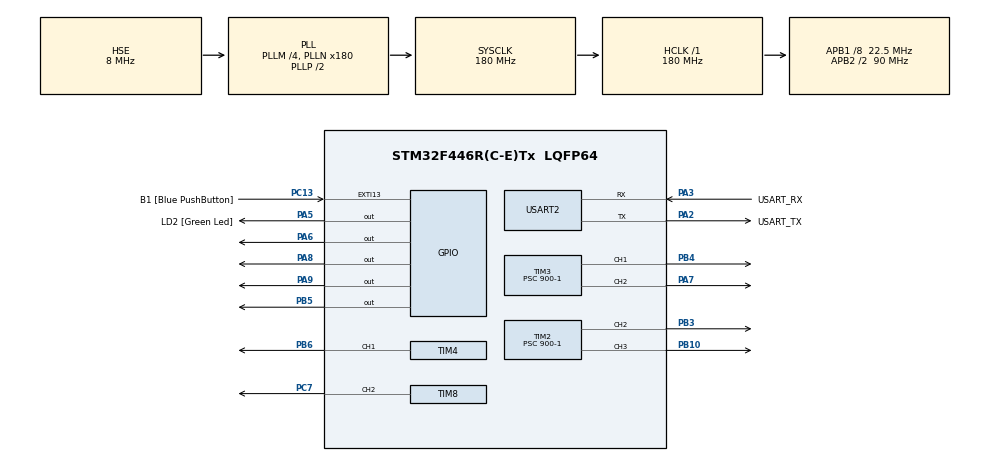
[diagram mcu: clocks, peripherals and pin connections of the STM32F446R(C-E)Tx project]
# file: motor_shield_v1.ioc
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Dma.Request0=USART2_RX
Dma.USART2_RX.0.Direction=DMA_PERIPH_TO_MEMORY
Dma.USART2_RX.0.FIFOMode=DMA_FIFOMODE_DISABLE
Dma.USART2_RX.0.Instance=DMA1_Stream5
Dma.USART2_RX.0.MemDataAlignment=DMA_MDATAALIGN_BYTE
Dma.USART2_RX.0.MemInc=DMA_MINC_ENABLE
Dma.USART2_RX.0.Mode=DMA_NORMAL
Dma.USART2_RX.0.PeriphDataAlignment=DMA_PDATAALIGN_BYTE
Dma.USART2_RX.0.PeriphInc=DMA_PINC_DISABLE
Dma.USART2_RX.0.Priority=DMA_PRIORITY_LOW
Mcu.Family=STM32F4
Mcu.Name=STM32F446R(C-E)Tx
Mcu.Package=LQFP64
NVIC.DMA1_Stream5_IRQn=true\:0\:0\:false\:false\:true\:false\:true\:true
NVIC.PriorityGroup=NVIC_PRIORITYGROUP_0
NVIC.USART2_IRQn=true\:0\:0\:false\:false\:true\:true\:true\:true
PA13.GPIO_Label=TMS
PA13.Mode=Serial_Wire
PA13.Signal=SYS_JTMS-SWDIO
PA14.GPIO_Label=TCK
PA14.Mode=Serial_Wire
PA14.Signal=SYS_JTCK-SWCLK
PA2.GPIO_Label=USART_TX
PA2.Mode=Asynchronous
PA2.Signal=USART2_TX
PA3.GPIO_Label=USART_RX
PA3.Mode=Asynchronous
PA3.Signal=USART2_RX
PA5.GPIO_Label=LD2 [Green Led]
PA5.Signal=GPIO_Output
PA6.Signal=GPIO_Output
PA7.Signal=S_TIM3_CH2
PA8.Signal=GPIO_Output
PA9.Signal=GPIO_Output
PB10.Signal=S_TIM2_CH3
PB3.Signal=S_TIM2_CH2
PB4.Signal=S_TIM3_CH1
PB5.Signal=GPIO_Output
PB6.Signal=S_TIM4_CH1
PC13.GPIO_Label=B1 [Blue PushButton]
PC13.GPIO_ModeDefaultEXTI=GPIO_MODE_IT_FALLING
PC13.Signal=GPXTI13
PC14-OSC32_IN.Mode=LSE-External-Oscillator
PC14-OSC32_IN.Signal=RCC_OSC32_IN
PC15-OSC32_OUT.Mode=LSE-External-Oscillator
PC15-OSC32_OUT.Signal=RCC_OSC32_OUT
PC7.Signal=S_TIM8_CH2
PH0-OSC_IN.Mode=HSE-External-Oscillator
PH0-OSC_IN.Signal=RCC_OSC_IN
PH1-OSC_OUT.Mode=HSE-External-Oscillator
PH1-OSC_OUT.Signal=RCC_OSC_OUT
ProjectManager.HeapSize=0x200
ProjectManager.StackSize=0x400
ProjectManager.TargetToolchain=MDK-ARM V5.32
RCC.48MHZClocksFreq_Value=84000000
RCC.AHBFreq_Value=180000000
RCC.APB1CLKDivider=RCC_HCLK_DIV8
RCC.APB1Freq_Value=22500000
RCC.APB1TimFreq_Value=45000000
RCC.APB2CLKDivider=RCC_HCLK_DIV2
RCC.APB2Freq_Value=90000000
RCC.APB2TimFreq_Value=180000000
RCC.CortexFreq_Value=180000000
RCC.FLatency-AdvancedSettings=FLASH_LATENCY_5
RCC.HCLKFreq_Value=180000000
RCC.HSE_VALUE=8000000
RCC.HSI_VALUE=16000000
RCC.PLLM=4
RCC.PLLN=180
RCC.PLLSourceVirtual=RCC_PLLSOURCE_HSE
RCC.SYSCLKFreq_VALUE=180000000
RCC.SYSCLKSource=RCC_SYSCLKSOURCE_PLLCLK
RCC.USBFreq_Value=180000000
RCC.VCOOutputFreq_Value=360000000
SH.S_TIM2_CH2.0=TIM2_CH2,PWM Generation2 CH2
SH.S_TIM2_CH3.0=TIM2_CH3,PWM Generation3 CH3
SH.S_TIM3_CH1.0=TIM3_CH1,PWM Generation1 CH1
SH.S_TIM3_CH2.0=TIM3_CH2,PWM Generation2 CH2
SH.S_TIM4_CH1.0=TIM4_CH1,PWM Generation1 CH1
SH.S_TIM8_CH2.0=TIM8_CH2,PWM Generation2 CH2
TIM2.Channel-PWM\ Generation2\ CH2=TIM_CHANNEL_2
TIM2.Channel-PWM\ Generation3\ CH3=TIM_CHANNEL_3
TIM2.Period=1000-1
TIM2.Prescaler=900-1
TIM3.Channel-PWM\ Generation1\ CH1=TIM_CHANNEL_1
TIM3.Channel-PWM\ Generation2\ CH2=TIM_CHANNEL_2
TIM3.Period=1000-1
TIM3.Prescaler=900-1
TIM4.Channel-PWM\ Generation1\ CH1=TIM_CHANNEL_1
TIM4.Period=1000-1
TIM4.Prescaler=900-1
TIM8.Channel-PWM\ Generation2\ CH2=TIM_CHANNEL_2
TIM8.Period=1000-1
TIM8.Prescaler=900-1
USART2.VirtualMode=VM_ASYNC
VP_TIM2_VS_ClockSourceINT.Mode=Internal
VP_TIM3_VS_ClockSourceINT.Mode=Internal
VP_TIM4_VS_ClockSourceINT.Mode=Internal
VP_TIM8_VS_ClockSourceINT.Mode=Internal
board=NUCLEO-F446RE

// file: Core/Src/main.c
/* USER CODE BEGIN Header */
/**
  ******************************************************************************
  * @file           : main.c
  * @brief          : Main program body
  ******************************************************************************
  * @attention
  *
  * Copyright (c) 2023 STMicroelectronics.
  * All rights reserved.
  *
  * This software is licensed under terms that can be found in the LICENSE file
  * in the root directory of this software component.
  * If no LICENSE file comes with this software, it is provided AS-IS.
  *
  ******************************************************************************
  */
/* USER CODE END Header */
#include "main.h"
#include "dma.h"
#include "tim.h"
#include "usart.h"
#include "gpio.h"

void SystemClock_Config(void);

int main(void)
{

  /* MCU Configuration--------------------------------------------------------*/

  /* Reset of all peripherals, Initializes the Flash interface and the Systick. */
  HAL_Init();

  /* Configure the system clock */
  SystemClock_Config();

  /* Initialize all configured peripherals */
  MX_GPIO_Init();
  MX_DMA_Init();
  MX_USART2_UART_Init();
  MX_TIM4_Init();
  MX_TIM3_Init();
  MX_TIM8_Init();
  MX_TIM2_Init();
  /* USER CODE BEGIN 2 */
	HAL_UARTEx_ReceiveToIdle_DMA(&huart2, RxBuf, RxBuf_SIZE);
	__HAL_DMA_DISABLE_IT(&hdma_usart2_rx, DMA_IT_HT);

	/* USER CODE END 2 */

  /* Infinite loop */
  /* USER CODE BEGIN WHILE */

	printf("Test start\r\n"); // Print for debug.
	core_config();
	ms1_motor_control(&motor_shield_v1,M1,1,1000);

  while (1)
  {
    /* USER CODE END WHILE */

    /* USER CODE BEGIN 3 */
//		for(int i=0;i<1000;i++){
//			int get_pwm = pwm_set(&servo_1,i);
//			printf("i= %3d, limit= %d\r\n",i,get_pwm);
//			HAL_Delay(50);
//		}
//		for(int i=1000-1;i>=0;i--){
//			int get_pwm = pwm_set(&servo_1,i);
//			printf("i= %3d, limit= %d\r\n",i,get_pwm);
//			HAL_Delay(50);
//		}

  }
  /* USER CODE END 3 */
}

void SystemClock_Config(void)
{
  RCC_OscInitTypeDef RCC_OscInitStruct = {0};
  RCC_ClkInitTypeDef RCC_ClkInitStruct = {0};

  /** Configure the main internal regulator output voltage
  */
  __HAL_RCC_PWR_CLK_ENABLE();
  __HAL_PWR_VOLTAGESCALING_CONFIG(PWR_REGULATOR_VOLTAGE_SCALE1);

  /** Initializes the RCC Oscillators according to the specified parameters
  * in the RCC_OscInitTypeDef structure.
  */
  RCC_OscInitStruct.OscillatorType = RCC_OSCILLATORTYPE_HSE;
  RCC_OscInitStruct.HSEState = RCC_HSE_ON;
  RCC_OscInitStruct.PLL.PLLState = RCC_PLL_ON;
  RCC_OscInitStruct.PLL.PLLSource = RCC_PLLSOURCE_HSE;
  RCC_OscInitStruct.PLL.PLLM = 4;
  RCC_OscInitStruct.PLL.PLLN = 180;
  RCC_OscInitStruct.PLL.PLLP = RCC_PLLP_DIV2;
  RCC_OscInitStruct.PLL.PLLQ = 2;
  RCC_OscInitStruct.PLL.PLLR = 2;
  if (HAL_RCC_OscConfig(&RCC_OscInitStruct) != HAL_OK)
  {
    Error_Handler();
  }

  /** Activate the Over-Drive mode
  */
  if (HAL_PWREx_EnableOverDrive() != HAL_OK)
  {
    Error_Handler();
  }

  /** Initializes the CPU, AHB and APB buses clocks
  */
  RCC_ClkInitStruct.ClockType = RCC_CLOCKTYPE_HCLK|RCC_CLOCKTYPE_SYSCLK
                              |RCC_CLOCKTYPE_PCLK1|RCC_CLOCKTYPE_PCLK2;
  RCC_ClkInitStruct.SYSCLKSource = RCC_SYSCLKSOURCE_PLLCLK;
  RCC_ClkInitStruct.AHBCLKDivider = RCC_SYSCLK_DIV1;
  RCC_ClkInitStruct.APB1CLKDivider = RCC_HCLK_DIV8;
  RCC_ClkInitStruct.APB2CLKDivider = RCC_HCLK_DIV2;

  if (HAL_RCC_ClockConfig(&RCC_ClkInitStruct, FLASH_LATENCY_5) != HAL_OK)
  {
    Error_Handler();
  }
}

void Error_Handler(void)
{
  __disable_irq();
  while (1)
  {
  }
}
